# TPTC register map
Vendor: Texas Instruments
Peripheral module from a debugger description file (folder radar).
Registers are 32-bit, read-only, no defined reset value unless marked. A register's access mark holds for its fields unless they carry their own. Offsets are as the file gives them; lines under a group give offsets from that group; [hi:lo] are bit positions; {n}, {i} and the like mark numbered series; 'fields as' and 'values as' point back to an identical list; <NAME> marks a mode.

## TPTC
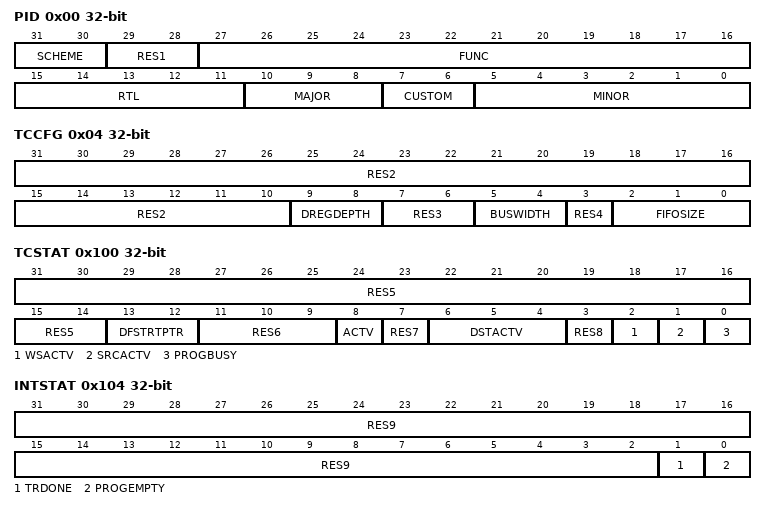
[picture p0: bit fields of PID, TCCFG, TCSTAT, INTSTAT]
0x00 PID — Peripheral ID Register
  [31:30] SCHEME — PID Scheme: Used to distinguish between old ID scheme and current. Spare bit to encode future schemes EDMA uses 'new scheme' indicated with value of 0x1.
  [29:28] RES1 — RESERVE FIELD
  [27:16] FUNC — Function indicates a software compatible module family.
  [15:11] RTL — RTL Version
  [10:8] MAJOR — Major Revision
  [7:6] CUSTOM — Custom revision field: Not used on this version of EDMA.
  [5:0] MINOR — Minor Revision
0x04 TCCFG — TC Configuration Register
  [31:10] RES2 — RESERVE FIELD
  [9:8] DREGDEPTH — Dst Register FIFO Depth Parameterization
  [7:6] RES3 — RESERVE FIELD
  [5:4] BUSWIDTH — Bus Width Parameterization
  [3] RES4 — RESERVE FIELD
  [2:0] FIFOSIZE — Fifo Size Parameterization
0x100 TCSTAT — TC Status Register
  [31:14] RES5 — RESERVE FIELD
  [13:12] DFSTRTPTR — Dst FIFO Start Pointer Represents the offset to the head entry of Dst Register FIFO in units of entries. Legal values = 0x0 to 0x3
  [11:9] RES6 — RESERVE FIELD
  [8] ACTV — Channel Active Channel Active is a logical-OR of each of the BUSY/ACTV signals. The ACTV bit must remain high through the life of a TR. ACTV = 0 : Channel is idle. ACTV = 1 : Channel is busy.
  [7] RES7 — RESERVE FIELD
  [6:4] DSTACTV — Destination Active State Specifies the number of TRs that are resident in the Dst Register FIFO at a given instant. Legal values are constrained by the DSTREGDEPTH parameter.
  [3] RES8 — RESERVE FIELD
  [2] WSACTV — Write Status Active WSACTV = 0 : Write status is not pending. Write status has been received for all previously issued write commands. WSACTV = 1 : Write Status is pending. Write status has not been received for all previously issued write commands.
  [1] SRCACTV — Source Active State SRCACTV = 0 : Source Active set is idle. Any TR written to Prog Set will immediately transition to Source Active set as long as the Dst FIFO Set is not full (DSTFULL == 1). SRCACTV = 1 : Source Active set is busy either performing read transfers or waiting to perform read transfers for current Transfer Request.
  [0] PROGBUSY — Program Register Set Busy PROGBUSY = 0 : Prog set idle and is available for programming. PROGBUSY = 1 : Prog set busy. User should poll for PROGBUSY equal to '0' prior to re-programming the Program Register set.
0x104 INTSTAT — Interrupt Status Register
  [31:2] RES9 — RESERVE FIELD
  [1] TRDONE — TR Done Event Status: TRDONE = 0 : Condition not detected. TRDONE = 1 : Set when TC has completed a Transfer Request. TRDONE should be set when the write status is returned for the final write of a TR. Cleared when user writes '1' to INTCLR.TRDONE register bit.
  [0] PROGEMPTY — Program Set Empty Event Status: PROGEMPTY = 0 : Condition not detected. PROGEMPTY = 1 : Set when Program Register set transitions to empty state. Cleared when user writes '1' to INTCLR.PROGEMPTY register bit.
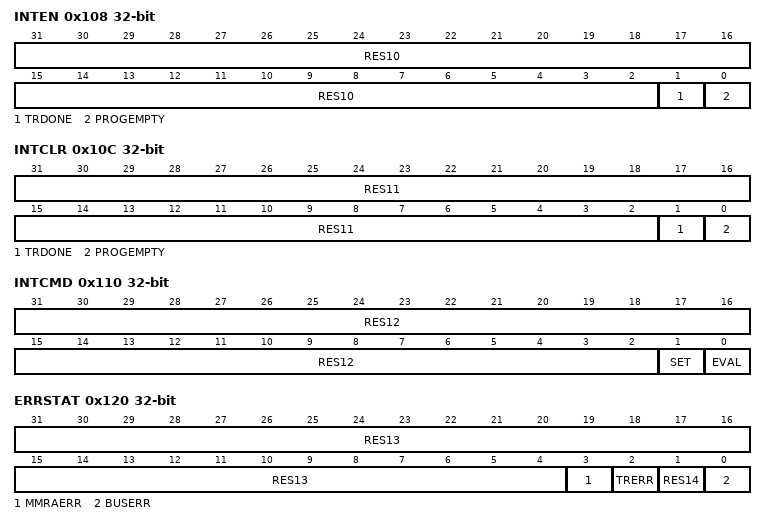
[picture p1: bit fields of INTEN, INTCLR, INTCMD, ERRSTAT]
0x108 INTEN access per field — Interrupt Enable Register
  [31:2] RES10 ro — RESERVE FIELD
  [1] TRDONE rw — TR Done Event Enable: INTEN.TRDONE = 0 : TRDONE Event is disabled. INTEN.TRDONE = 1 : TRDONE Event is enabled and contributes to interrupt generation
  [0] PROGEMPTY rw — Program Set Empty Event Enable: INTEN.PROGEMPTY = 0 : PROGEMPTY Event is disabled. INTEN.PROGEMPTY = 1 : PROGEMPTY Event is enabled and contributes to interrupt generation
0x10C INTCLR access per field — Interrupt Clear Register
  [31:2] RES11 ro — RESERVE FIELD
  [1] TRDONE wo — TR Done Event Clear: INTCLR.TRDONE = 0 : Writes of '0' have no effect.. INTCLR.TRDONE = 1 : Write of '1' clears INTSTAT.TRDONE bit
  [0] PROGEMPTY wo — Program Set Empty Event Clear: INTCLR.PROGEMPTY = 0 : Writes of '0' have no effect.. INTCLR.PROGEMPTY = 1 : Write of '1' clears INTSTAT.PROGEMPTY bit
0x110 INTCMD access per field — Interrupt Command Register
  [31:2] RES12 ro — RESERVE FIELD
  [1] SET wo — Set TPTC interrupt: Write of '1' to SET causes TPTC interrupt to be pulsed unconditionally. Writes of '0' have no affect.
  [0] EVAL wo — Evaluate state of TPTC interrupt Write of '1' to EVAL causes TPTC interrupt to be pulsed if any of the INTSTAT bits are set to '1'. Writes of '0' have no affect.
0x120 ERRSTAT — Error Status Register
  [31:4] RES13 — RESERVE FIELD
  [3] MMRAERR — MMR Address Error: MMRAERR = 0 : Condition not detected. MMRAERR = 1 : User attempted to read or write to invalid address configuration memory map. (Is only be set for non-emulation accesses). No additional error information is recorded.
  [2] TRERR — TR Error: TR detected that violates FIFO Mode transfer (SAM or DAM is '1') alignment rules or has ACNT or BCNT == 0. No additional error information is recorded.
  [1] RES14 — RESERVE FIELD
  [0] BUSERR — Bus Error Event: BUSERR = 0: Condition not detected. BUSERR = 1: TC has detected an error code on the write response bus or read response bus. Error information is stored in Error Details Register (ERRDET).
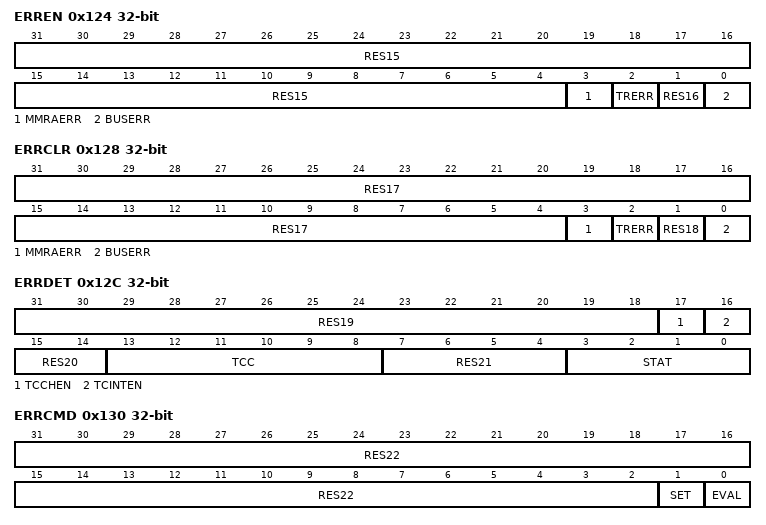
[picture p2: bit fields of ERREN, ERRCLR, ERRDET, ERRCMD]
0x124 ERREN access per field — Error Enable Register
  [31:4] RES15 ro — RESERVE FIELD
  [3] MMRAERR rw — Interrupt enable for ERRSTAT.MMRAERR: ERREN.MMRAERR = 0 : BUSERR is disabled. ERREN.MMRAERR = 1 : MMRAERR is enabled and contributes to the TPTC error interrupt generation.
  [2] TRERR rw — Interrupt enable for ERRSTAT.TRERR: ERREN.TRERR = 0 : BUSERR is disabled. ERREN.TRERR = 1 : TRERR is enabled and contributes to the TPTC error interrupt generation.
  [1] RES16 ro — RESERVE FIELD
  [0] BUSERR rw — Interrupt enable for ERRSTAT.BUSERR: ERREN.BUSERR = 0 : BUSERR is disabled. ERREN.BUSERR = 1 : BUSERR is enabled and contributes to the TPTC error interrupt generation.
0x128 ERRCLR access per field — Error Clear Register
  [31:4] RES17 ro — RESERVE FIELD
  [3] MMRAERR wo — Interrupt clear for ERRSTAT.MMRAERR: ERRCLR.MMRAERR = 0 : Writes of '0' have no effect.. ERRCLR.MMRAERR = 1 : Write of '1' clears ERRSTAT.MMRAERR bit. Write of '1' to ERRCLR.MMRAERR does not clear the ERRDET register.
  [2] TRERR wo — Interrupt clear for ERRSTAT.TRERR: ERRCLR.TRERR = 0 : Writes of '0' have no effect.. ERRCLR.TRERR = 1 : Write of '1' clears ERRSTAT.TRERR bit. Write of '1' to ERRCLR.TRERR does not clear the ERRDET register.
  [1] RES18 ro — RESERVE FIELD
  [0] BUSERR wo — Interrupt clear for ERRSTAT.BUSERR: ERRCLR.BUSERR = 0 : Writes of '0' have no effect.. ERRCLR.BUSERR = 1 : Write of '1' clears ERRSTAT.BUSERR bit. Write of '1' to ERRCLR.BUSERR clears the ERRDET register.
0x12C ERRDET — Error Details Register
  [31:18] RES19 — RESERVE FIELD
  [17] TCCHEN — Contains the OPT.TCCHEN value programmed by the user for the Read or Write transaction that resulted in an error.
  [16] TCINTEN — Contains the OPT.TCINTEN value programmed by the user for the Read or Write transaction that resulted in an error.
  [15:14] RES20 — RESERVE FIELD
  [13:8] TCC — Transfer Complete Code: Contains the OPT.TCC value programmed by the user for the Read or Write transaction that resulted in an error.
  [7:4] RES21 — RESERVE FIELD
  [3:0] STAT — Transaction Status: Stores the non-zero status/error code that was detected on the read status or write status bus. MS-bit effectively serves as the read vs. write error code. If read status and write status are returned on the same cycle then the TC chooses non-zero version. If both are non-zero then write status is treated as higher priority. Encoding of errors matches the CBA spec and is summarized here: 0xF =
0x130 ERRCMD access per field — Error Command Register
  [31:2] RES22 ro — RESERVE FIELD
  [1] SET wo — Set TPTC error interrupt: Write of '1' to SET causes TPTC error interrupt to be pulsed unconditionally. Writes of '0' have no affect.
  [0] EVAL wo — Evaluate state of TPTC error interrupt Write of '1' to EVAL causes TPTC error interrupt to be pulsed if any of the ERRSTAT bits are set to '1'. Writes of '0' have no affect.
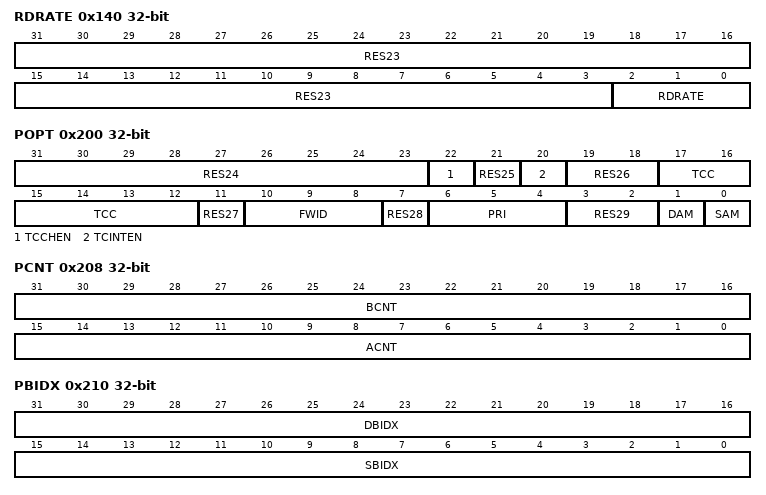
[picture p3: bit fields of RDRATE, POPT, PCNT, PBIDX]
0x140 RDRATE access per field — Read Rate Register
  [31:3] RES23 ro — RESERVE FIELD
  [2:0] RDRATE rw — Read Rate Control: Controls the number of cycles between read commands. This is a global setting that applies to all TRs for this TC.
0x200 POPT access per field — Prog Set Options
  [31:23] RES24 ro — RESERVE FIELD
  [22] TCCHEN rw — Transfer complete chaining enable: 0: Transfer complete chaining is disabled. 1: Transfer complete chaining is enabled.
  [21] RES25 ro — RESERVE FIELD
  [20] TCINTEN rw — Transfer complete interrupt enable: 0: Transfer complete interrupt is disabled. 1: Transfer complete interrupt is enabled.
  [19:18] RES26 ro — RESERVE FIELD
  [17:12] TCC rw — Transfer Complete Code: The 6-bit code is used to set the relevant bit in CER or IPR of the TPCC module.
  [11] RES27 ro — RESERVE FIELD
  [10:8] FWID rw — FIFO width control: Applies if either SAM or DAM is set to FIFO mode.
  [7] RES28 ro — RESERVE FIELD
  [6:4] PRI rw — Transfer Priority: 0: Priority 0 - Highest priority 1: Priority 1 ... 7: Priority 7 - Lowest priority
  [3:2] RES29 ro — RESERVE FIELD
  [1] DAM rw — Destination Address Mode within an array: 0: INCR Dst addressing within an array increments. 1: FIFO Dst addressing within an array wraps around upon reaching FIFO width.
  [0] SAM rw — Source Address Mode within an array: 0: INCR Src addressing within an array increments. 1: FIFO Src addressing within an array wraps around upon reaching FIFO width.
0x204 PSRC rw — Prog Set Src Address
  [31:0] SADDR — Source address for Program Register Set
0x208 PCNT rw — Prog Set Count
  [31:16] BCNT — B-Dimension count. Number of arrays to be transferred where each array is ACNT in length.
  [15:0] ACNT — A-Dimension count. Number of bytes to be transferred in first dimension.
0x20C PDST rw — Prog Set Dst Address
  [31:0] DADDR — Destination address for Program Register Set
0x210 PBIDX rw — Prog Set B-Dim Idx
  [31:16] DBIDX — Dest B-Idx for Program Register Set: B-Idx offset between Destination arrays: Represents the offset in bytes between the starting address of each destination array (recall that there are BCNT arrays of ACNT elements). DBIDX is always used regardless of whether DAM is Increment or FIFO mode.
  [15:0] SBIDX — Source B-Idx for Program Register Set: B-Idx offset between Source arrays: Represents the offset in bytes between the starting address of each source array (recall that there are BCNT arrays of ACNT elements). SBIDX is always used regardless of whether SAM is Increment or FIFO mode.
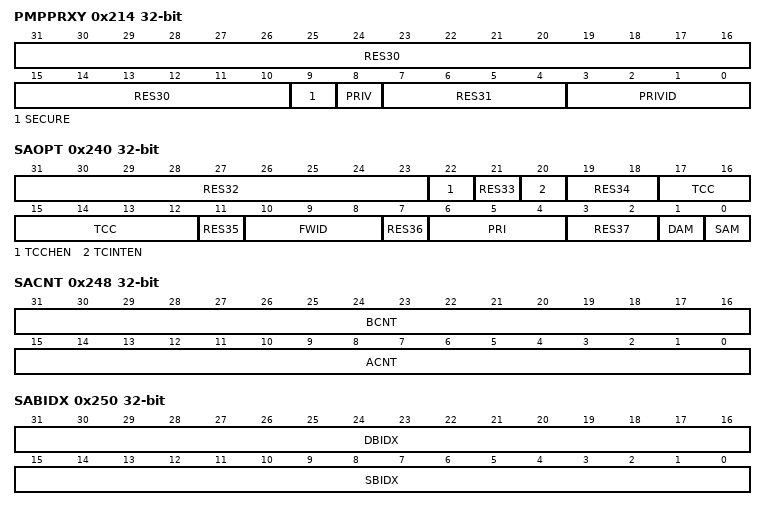
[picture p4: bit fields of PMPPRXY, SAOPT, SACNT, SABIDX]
0x214 PMPPRXY — Prog Set Mem Protect Proxy
  [31:10] RES30 — RESERVE FIELD
  [9] SECURE — Secure Level: SECURE = 0 : Non-secure access SECURE = 1 : Secure access PMPPRXY.SECURE is always updated with the value from the configuration bus secure field on any/every write to Program Set BIDX Register (trigger register). The SECURE value for the SA Set and DF Set are copied from the value in the Program set along with the remainder of the parameter values. The secure attribute is issued on the VBusM read and write command bus such that the target endpoints can perform memory protection and security checks based on the SECURE level of the external host that sets up the DMA transaction.
  [8] PRIV — Privilege Level: PRIV = 0 : User level privilege PRIV = 1 : Supervisor level privilege PMPPRXY.PRIV is always updated with the value from the configuration bus privilege field on any/every write to Program Set BIDX Register (trigger register). The PRIV value for the SA Set and DF Set are copied from the value in the Program set along with the remainder of the parameter values. The privilege ID is issued on the VBusM read and write command bus such that the target endpoints can perform memory protection checks based on the PRIV of the external host that sets up the DMA transaction.
  [7:4] RES31 — RESERVE FIELD
  [3:0] PRIVID — Privilege ID: PMPPRXY.PRIVID is always updated with the value from configuration bus privilege ID field on any/every write to Program Set BIDX Register (trigger register). The PRIVID value for the SA Set and DF Set are copied from the value in the Program set along with the remainder of the parameter values. The privilege ID is issued on the VBusM read and write command bus such that the target endpoints can perform memory protection checks based on the privid of the external host that sets up the DMA transaction.
0x240 SAOPT — Src Actv Set Options
  [31:23] RES32 — RESERVE FIELD
  [22] TCCHEN — Transfer complete chaining enable: 0: Transfer complete chaining is disabled. 1: Transfer complete chaining is enabled.
  [21] RES33 — RESERVE FIELD
  [20] TCINTEN — Transfer complete interrupt enable: 0: Transfer complete interrupt is disabled. 1: Transfer complete interrupt is enabled.
  [19:18] RES34 — RESERVE FIELD
  [17:12] TCC — Transfer Complete Code: The 6-bit code is used to set the relevant bit in CER or IPR of the TPCC module.
  [11] RES35 — RESERVE FIELD
  [10:8] FWID — FIFO width control: Applies if either SAM or DAM is set to FIFO mode.
  [7] RES36 — RESERVE FIELD
  [6:4] PRI — Transfer Priority: 0: Priority 0 - Highest priority 1: Priority 1 ... 7: Priority 7 - Lowest priority
  [3:2] RES37 — RESERVE FIELD
  [1] DAM — Destination Address Mode within an array: 0: INCR Dst addressing within an array increments. 1: FIFO Dst addressing within an array wraps around upon reaching FIFO width.
  [0] SAM — Source Address Mode within an array: 0: INCR Src addressing within an array increments. 1: FIFO Src addressing within an array wraps around upon reaching FIFO width.
0x244 SASRC — Src Actv Set Src Address
  [31:0] SADDR — Source address for Source Active Register Set: Initial value is copied from PSRC.SADDR. TC updates value according to source addressing mode (OPT.SAM) and/or source index value (BIDX.SBIDX) after each read command is issued. When a TR is complete the final value should be the address of the last read command issued.
0x248 SACNT — Src Actv Set Count
  [31:16] BCNT — B-Dimension count: Number of arrays to be transferred where each array is ACNT in length. Count Remaining for Src Active Register Set. Represents the amount of data remaining to be read. Initial value is copied from PCNT. TC decrements ACNT and BCNT as necessary after each read command is issued. Final value should be 0 when TR is complete.
  [15:0] ACNT — A-Dimension count: Number of bytes to be transferred in first dimension. Count Remaining for Src Active Register Set. Represents the amount of data remaining to be read. Initial value is copied from PCNT. TC decrements ACNT and BCNT as necessary after each read command is issued. Final value should be 0 when TR is complete.
0x250 SABIDX — Src Actv Set B-Dim Idx
  [31:16] DBIDX — Dest B-Idx for Source Active Register Set. Value copied from PBIDX: B-Idx offset between Destination arrays: Represents the offset in bytes between the starting address of each destination array (recall that there are BCNT arrays of ACNT elements). DBIDX is always used regardless of whether DAM is Increment or FIFO mode.
  [15:0] SBIDX — Source B-Idx for Source Active Register Set. Value copied from PBIDX: B-Idx offset between Source arrays: Represents the offset in bytes between the starting address of each source array (recall that there are BCNT arrays of ACNT elements). SBIDX is always used regardless of whether SAM is Increment or FIFO mode.
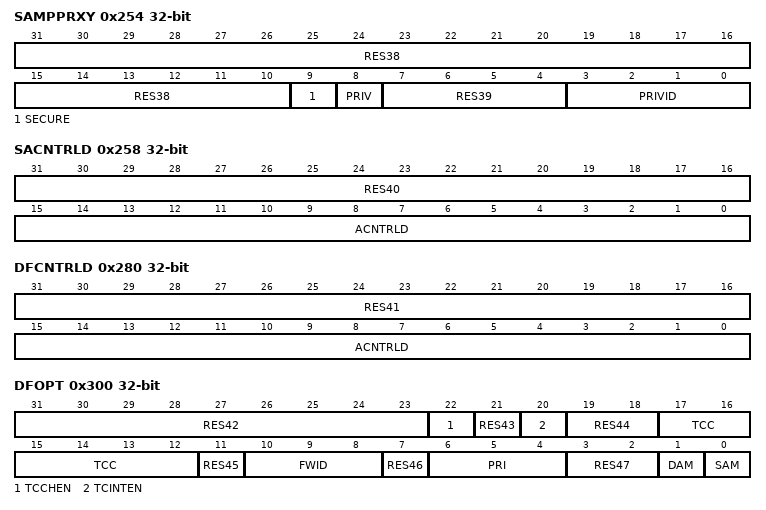
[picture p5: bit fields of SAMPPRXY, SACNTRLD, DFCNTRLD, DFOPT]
0x254 SAMPPRXY — Src Actv Set Mem Protect Proxy
  [31:10] RES38 — RESERVE FIELD
  [9] SECURE — Secure Level: SECURE = 0 : Non-secure access SECURE = 1 : Secure access SAMPPRXY.SECURE is always updated with the value from the configuration bus secure field on any/every write to Program Set BIDX Register (trigger register). The SECURE value for the SA Set and DF Set are copied from the value in the Program set along with the remainder of the parameter values. The secure attribute is issued on the VBusM read and write command bus such that the target endpoints can perform memory protection and security checks based on the SECURE level of the external host that sets up the DMA transaction.
  [8] PRIV — Privilege Level: PRIV = 0 : User level privilege PRIV = 1 : Supervisor level privilege SAMPPRXY.PRIV is always updated with the value from the configuration bus privilege field on any/every write to Program Set BIDX Register (trigger register). The PRIV value for the SA Set and DF Set are copied from the value in the Program set along with the remainder of the parameter values. The privilege ID is issued on the VBusM read and write command bus such that the target endpoints can perform memory protection checks based on the PRIV of the external host that sets up the DMA transaction.
  [7:4] RES39 — RESERVE FIELD
  [3:0] PRIVID — Privilege ID: SAMPPRXY.PRIVID is always updated with the value from configuration bus privilege ID field on any/every write to Program Set BIDX Register (trigger register). The PRIVID value for the SA Set and DF Set are copied from the value in the Program set along with the remainder of the parameter values. The privilege ID is issued on the VBusM read and write command bus such that the target endpoints can perform memory protection checks based on the privid of the external host that sets up the DMA transaction.
0x258 SACNTRLD — Src Actv Set Cnt Reload
  [31:16] RES40 — RESERVE FIELD
  [15:0] ACNTRLD — A-Cnt Reload value for Source Active Register set. Value copied from PCNT.ACNT: Represents the originally programmed value of ACNT. The Reload value is used to reinitialize ACNT after each array is serviced (i.e. ACNT decrements to 0). by the Src offset in bytes between the starting address of each source array (recall that there are BCNT arrays of ACNT bytes)
0x25C SASRCBREF — Src Actv Set Src Addr A-Reference
  [31:0] SADDRBREF — Source address reference for Source Active Register Set: Represents the starting address for the array currently being read. The next array's starting address is calculated as the 'reference address' plus the 'source b-idx' value.
0x260 SADSTBREF — rsvd return 0x0 w/o AERROR
  [31:0] DADDRBREF — Dst address reference is not applicable for Src Active Register Set. Reads return 0x0.
0x280 DFCNTRLD — Dst FIFO Set Cnt Reload
  [31:16] RES41 — RESERVE FIELD
  [15:0] ACNTRLD — A-Cnt Reload value for Destination FIFO Register set. Value copied from PCNT.ACNT: Represents the originally programmed value of ACNT. The Reload value is used to reinitialize ACNT after each array is serviced (i.e. ACNT decrements to 0). by the Src offset in bytes between the starting address of each source array (recall that there are BCNT arrays of ACNT bytes)
0x284 DFSRCBREF — rsvd return 0x0 w/o AERROR
  [31:0] SADDRBREF — Source address reference is not applicable for Dst FIFO Register Set. Reads return 0x0.
0x300 DFOPT — Dst FIFO Set Options
  [31:23] RES42 — RESERVE FIELD
  [22] TCCHEN — Transfer complete chaining enable: 0: Transfer complete chaining is disabled. 1: Transfer complete chaining is enabled.
  [21] RES43 — RESERVE FIELD
  [20] TCINTEN — Transfer complete interrupt enable: 0: Transfer complete interrupt is disabled. 1: Transfer complete interrupt is enabled.
  [19:18] RES44 — RESERVE FIELD
  [17:12] TCC — Transfer Complete Code: The 6-bit code is used to set the relevant bit in CER or IPR of the TPCC module.
  [11] RES45 — RESERVE FIELD
  [10:8] FWID — FIFO width control: Applies if either SAM or DAM is set to FIFO mode.
  [7] RES46 — RESERVE FIELD
  [6:4] PRI — Transfer Priority: 0: Priority 0 - Highest priority 1: Priority 1 ... 7: Priority 7 - Lowest priority
  [3:2] RES47 — RESERVE FIELD
  [1] DAM — Destination Address Mode within an array: 0: INCR Dst addressing within an array increments. 1: FIFO Dst addressing within an array wraps around upon reaching FIFO width.
  [0] SAM — Source Address Mode within an array: 0: INCR Src addressing within an array increments. 1: FIFO Src addressing within an array wraps around upon reaching FIFO width.
0x304 DFSRC — rsvd return 0x0 w/o AERROR
  [31:0] SADDR — Source address is not applicable for Dst FIFO Register Set: Reads return 0x0.
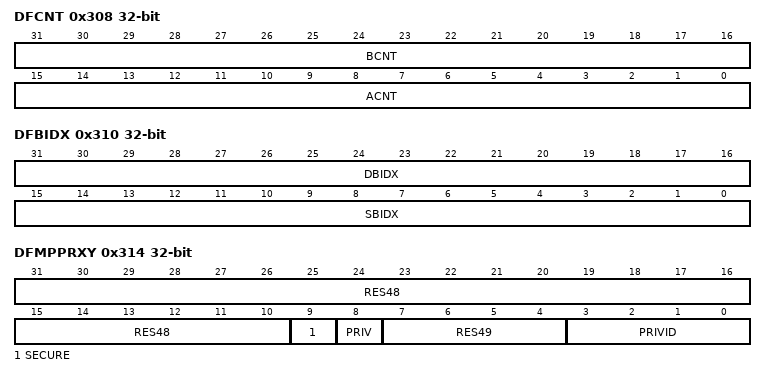
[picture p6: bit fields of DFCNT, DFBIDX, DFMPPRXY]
0x308 DFCNT — Dst FIFO Set Count
  [31:16] BCNT — B-Count Remaining for Dst Register Set: Number of arrays to be transferred where each array is ACNT in length. Represents the amount of data remaining to be written. Initial value is copied from PCNT. TC decrements ACNT and BCNT as necessary after each write dataphase is issued. Final value should be 0 when TR is complete.
  [15:0] ACNT — A-Count Remaining for Dst Register Set: Number of bytes to be transferred in first dimension. Represents the amount of data remaining to be written. Initial value is copied from PCNT. TC decrements ACNT and BCNT as necessary after each write dataphase is issued. Final value should be 0 when TR is complete.
0x30C DFDST — Dst FIFO Set Dst Address
  [31:0] DADDR — Destination address for Dst FIFO Register Set: Initial value is copied from PDST.DADDR. TC updates value according to destination addressing mode (OPT.SAM) and/or dest index value (BIDX.DBIDX) after each write command is issued. When a TR is complete the final value should be the address of the last write command issued.
0x310 DFBIDX — Dst FIFO Set B-Dim Idx
  [31:16] DBIDX — Dest B-Idx for Dest FIFO Register Set. Value copied from PBIDX: B-Idx offset between Destination arrays: Represents the offset in bytes between the starting address of each destination array (recall that there are BCNT arrays of ACNT elements). DBIDX is always used regardless of whether DAM is Increment or FIFO mode.
  [15:0] SBIDX — Dest B-Idx for Dest FIFO Register Set. Value copied from PBIDX: B-Idx offset between Source arrays: Represents the offset in bytes between the starting address of each source array (recall that there are BCNT arrays of ACNT elements). SBIDX is always used regardless of whether SAM is Increment or FIFO mode.
0x314 DFMPPRXY — Dst FIFO Mem Protect Proxy
  [31:10] RES48 — RESERVE FIELD
  [9] SECURE — Secure Level: SECURE = 0 : Non-secure access SECURE = 1 : Secure access DFMPPRXY0.SECURE is always updated with the value from the configuration bus secure field on any/every write to Program Set BIDX Register (trigger register). The SECURE value for the SA Set and DF Set are copied from the value in the Program set along with the remainder of the parameter values. The secure attribute is issued on the VBusM read and write command bus such that the target endpoints can perform memory protection and security checks based on the SECURE level of the external host that sets up the DMA transaction.
  [8] PRIV — Privilege Level: PRIV = 0 : User level privilege PRIV = 1 : Supervisor level privilege DFMPPRXY0.PRIV is always updated with the value from the configuration bus privilege field on any/every write to Program Set BIDX Register (trigger register). The PRIV value for the SA Set and DF Set are copied from the value in the Program set along with the remainder of the parameter values. The privilege ID is issued on the VBusM read and write command bus such that the target endpoints can perform memory protection checks based on the PRIV of the external host that sets up the DMA transaction.
  [7:4] RES49 — RESERVE FIELD
  [3:0] PRIVID — Privilege ID: DFMPPRXY0.PRIVID is always updated with the value from configuration bus privilege ID field on any/every write to Program Set BIDX Register (trigger register). The PRIVID value for the SA Set and DF Set are copied from the value in the Program set along with the remainder of the parameter values. The privilege ID is issued on the VBusM read and write command bus such that the target endpoints can perform memory protection checks based on the privid of the external host that sets up the DMA transaction.
